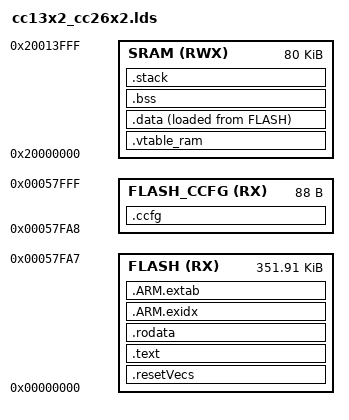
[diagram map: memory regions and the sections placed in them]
/*
 * Copyright (c) 2017-2018, Texas Instruments Incorporated
 * All rights reserved.
 *
 * Redistribution and use in source and binary forms, with or without
 * modification, are permitted provided that the following conditions
 * are met:
 *
 * *  Redistributions of source code must retain the above copyright
 *    notice, this list of conditions and the following disclaimer.
 *
 * *  Redistributions in binary form must reproduce the above copyright
 *    notice, this list of conditions and the following disclaimer in the
 *    documentation and/or other materials provided with the distribution.
 *
 * *  Neither the name of Texas Instruments Incorporated nor the names of
 *    its contributors may be used to endorse or promote products derived
 *    from this software without specific prior written permission.
 *
 * THIS SOFTWARE IS PROVIDED BY THE COPYRIGHT HOLDERS AND CONTRIBUTORS "AS IS"
 * AND ANY EXPRESS OR IMPLIED WARRANTIES, INCLUDING, BUT NOT LIMITED TO,
 * THE IMPLIED WARRANTIES OF MERCHANTABILITY AND FITNESS FOR A PARTICULAR
 * PURPOSE ARE DISCLAIMED. IN NO EVENT SHALL THE COPYRIGHT OWNER OR
 * CONTRIBUTORS BE LIABLE FOR ANY DIRECT, INDIRECT, INCIDENTAL, SPECIAL,
 * EXEMPLARY, OR CONSEQUENTIAL DAMAGES (INCLUDING, BUT NOT LIMITED TO,
 * PROCUREMENT OF SUBSTITUTE GOODS OR SERVICES; LOSS OF USE, DATA, OR PROFITS;
 * OR BUSINESS INTERRUPTION) HOWEVER CAUSED AND ON ANY THEORY OF LIABILITY,
 * WHETHER IN CONTRACT, STRICT LIABILITY, OR TORT (INCLUDING NEGLIGENCE OR
 * OTHERWISE) ARISING IN ANY WAY OUT OF THE USE OF THIS SOFTWARE,
 * EVEN IF ADVISED OF THE POSSIBILITY OF SUCH DAMAGE.
 */
/*
 *  ======== CC1352R1_LAUNCHXL_NoRTOS.lds ========
 *  Default Linker script for the Texas Instruments CC1352
 */

STACKSIZE = 512;

ENTRY(ResetISR)

FLASH_START       = 0x00000000;
FLASH_LENGTH      = 0x00057fa8;

FLASH_CCFG_START  = 0x00057fa8;
FLASH_CCFG_LENGTH = 0x00000058;

SRAM_START        = 0x20000000;
SRAM_LENGTH       = 0x00014000;

MEMORY
{
    FLASH (RX)      : ORIGIN = 0x00000000, LENGTH = 0x00057fa8
    FLASH_CCFG (RX) : ORIGIN = 0x00057fa8, LENGTH = 0x00000058
    SRAM (RWX)      : ORIGIN = 0x20000000, LENGTH = 0x00014000
}

REGION_ALIAS("REGION_TEXT",      FLASH);
REGION_ALIAS("REGION_BSS",       SRAM);
REGION_ALIAS("REGION_DATA",      SRAM);
REGION_ALIAS("REGION_STACK",     SRAM);
REGION_ALIAS("REGION_ARM_EXIDX", FLASH);
REGION_ALIAS("REGION_ARM_EXTAB", FLASH);

SECTIONS {

    PROVIDE (_resetVecs_base_address =
        DEFINED(_resetVecs_base_address) ? _resetVecs_base_address : 0x0);

    .resetVecs (_resetVecs_base_address) : AT (_resetVecs_base_address) {
        KEEP (*(.resetVecs))
    } > REGION_TEXT

    .vtable_ram (NOLOAD) : ALIGN(256) {
        KEEP (*(vtable_ram))
    } > REGION_DATA

    .text : {
        CREATE_OBJECT_SYMBOLS
        *(.text)
        *(.text.*)
        . = ALIGN(0x4);
        KEEP (*(.ctors))
        . = ALIGN(0x4);
        KEEP (*(.dtors))
        . = ALIGN(0x4);
        __init_array_start = .;
        KEEP (*(.init_array*))
        __init_array_end = .;
        *(.init)
        *(.fini*)
    } > REGION_TEXT AT> REGION_TEXT

    PROVIDE (__etext = .);
    PROVIDE (_etext = .);
    PROVIDE (etext = .);

    .rodata : {
        *(.rodata)
        *(.rodata.*)
    } > REGION_TEXT AT> REGION_TEXT

    .data : ALIGN(4) {
        __data_load__ = LOADADDR (.data);
        __data_start__ = .;
        *(.data)
        *(.data.*)
        . = ALIGN (4);
        __data_end__ = .;
    } > REGION_DATA AT> REGION_TEXT

    .ARM.exidx : {
        __exidx_start = .;
        *(.ARM.exidx* .gnu.linkonce.armexidx.*)
        __exidx_end = .;
    } > REGION_ARM_EXIDX AT> REGION_ARM_EXIDX

    .ARM.extab : {
        *(.ARM.extab* .gnu.linkonce.armextab.*)
    } > REGION_ARM_EXTAB AT> REGION_ARM_EXTAB

    .ccfg : {
        KEEP (*(.ccfg))
    } > FLASH_CCFG AT> FLASH_CCFG

    .bss : {
        __bss_start__ = .;
        *(.shbss)
        *(.bss)
        *(.bss.*)
        *(COMMON)
        . = ALIGN (4);
        __bss_end__ = .;
    } > REGION_BSS AT> REGION_BSS

    .stack (NOLOAD) : ALIGN(0x8) {
        _stack = .;
        __stack = .;
        KEEP(*(.stack))
        . += STACKSIZE;
        _stack_end = .;
        __stack_end = .;
    } > REGION_STACK AT> REGION_STACK
}
